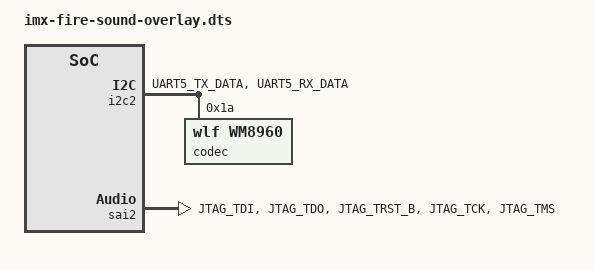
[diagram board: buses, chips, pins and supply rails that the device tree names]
/*
 * Copyright (C) 2019 - All Rights Reserved by 
 * filename : imx-fire-mpu6050-overlay.dts
 * brief : Device Tree overlay for EBF6ull Pro mpu6050 device
 * author : embedfire
 * date : 2019-11-26
 * version : A001
 */
#include "../imx6ul-pinfunc.h"
#include "../imx6ull-pinfunc.h"
#include "dt-bindings/clock/imx6ul-clock.h"

/dts-v1/;
/plugin/;

/ {
	fragment@1 {
         target = <&i2c2>;
         __overlay__ {
		 			clock_frequency = <100000>;
					pinctrl-names = "default";
					pinctrl-0 = <&pinctrl_i2c2>;
					status = "okay";
					#address-cells = <1>;
	    			#size-cells = <0>; 
 			
					codec: wm8960@1a {
						compatible = "wlf,wm8960";
						reg = <0x1a>;
						clocks = <&clks IMX6UL_CLK_SAI2>;
						clock-names = "mclk";
						wlf,shared-lrclk;
					};			      
         };
     };

	fragment@2{
		target-path="/";
		__overlay__{	
		   sound {		
			compatible = "fsl,imx6ul-evk-wm8960",
					 "fsl,imx-audio-wm8960";
			model = "wm8960-audio";
			cpu-dai = <&sai2>;
			audio-codec = <&codec>;
			asrc-controller = <&asrc>;
			codec-master;
			gpr = <&gpr 4 0x100000 0x100000>;
			/*
			 * hp-det = <hp-det-pin hp-det-polarity>;
			 * hp-det-pin: JD1 JD2  or JD3
			 * hp-det-polarity = 0: hp detect high for headphone
			 * hp-det-polarity = 1: hp detect high for speaker
			 */
			hp-det = <3 1>;
			/*hp-det-gpios = <&gpio5 4 0>;
			mic-det-gpios = <&gpio5 4 0>;*/
			audio-routing =
				"Headphone Jack", "HP_L",
				"Headphone Jack", "HP_R",
				"Ext Spk", "SPK_LP",
				"Ext Spk", "SPK_LN",
				"Ext Spk", "SPK_RP",
				"Ext Spk", "SPK_RN",
				"LINPUT2", "Mic Jack",
				"LINPUT3", "Mic Jack",
				"RINPUT1", "Main MIC",
				"RINPUT2", "Main MIC",
				"Mic Jack", "MICB",
				"Main MIC", "MICB",
				"CPU-Playback", "ASRC-Playback",
				"Playback", "CPU-Playback",
				"ASRC-Capture", "CPU-Capture",
				"CPU-Capture", "Capture";
				status = "okay";
			};		
		};
	};	


	fragment@3{
		target=<&iomuxc>;
		__overlay__ {
			 pinctrl_i2c2: i2c2grp {
				fsl,pins = <
					MX6UL_PAD_UART5_TX_DATA__I2C2_SCL 0x4001b8b0
					MX6UL_PAD_UART5_RX_DATA__I2C2_SDA 0x4001b8b0
				>;
			};
			pinctrl_sai2: sai2grp {
				fsl,pins = <
					MX6UL_PAD_JTAG_TDI__SAI2_TX_BCLK	0x17088
					MX6UL_PAD_JTAG_TDO__SAI2_TX_SYNC	0x17088
					MX6UL_PAD_JTAG_TRST_B__SAI2_TX_DATA	0x11088
					MX6UL_PAD_JTAG_TCK__SAI2_RX_DATA	0x11088
					MX6UL_PAD_JTAG_TMS__SAI2_MCLK		0x17088
				>;
			};
		};
	};
	
	fragment@4 {
		target=<&sai2>;
		__overlay__{
			pinctrl-names = "default";
			pinctrl-0 = <&pinctrl_sai2>;
			/*&pinctrl_sai2_hp_det_b>;*/

			assigned-clocks = <&clks IMX6UL_CLK_SAI2_SEL>,
			<&clks IMX6UL_CLK_SAI2>;
			assigned-clock-parents = <&clks IMX6UL_CLK_PLL4_AUDIO_DIV>;
			assigned-clock-rates = <0>, <12288000>;
			status = "okay";
		};
	};
};
